# PIC32MM0256GPM028 register map
Vendor: Microchip
Registers are 32-bit, read-write, reset 0x0 unless marked. A register's access mark holds for its fields unless they carry their own. Addresses are absolute, and some are shared; only a register's first bit layout is shown; [hi:lo] are bit positions; {n}, {i} and the like mark numbered series.

## UART1
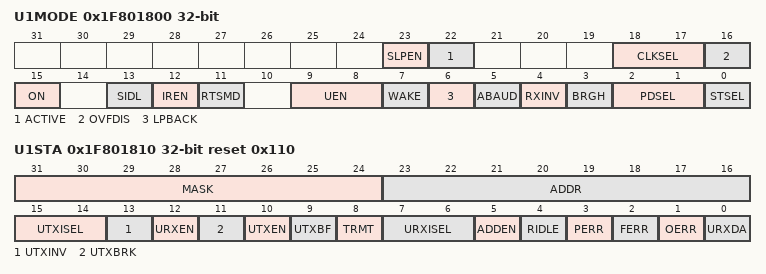
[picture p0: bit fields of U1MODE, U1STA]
0x1F801800 U1MODE
  [23] SLPEN, [22] ACTIVE, [18:17] CLKSEL, [16] OVFDIS, [15] ON, [13] SIDL, [12] IREN, [11] RTSMD, [9:8] UEN, [7] WAKE, [6] LPBACK, [5] ABAUD, [4] RXINV, [3] BRGH, [2:1] PDSEL, [0] STSEL
0x1F801810 U1STA reset 0x110
  [31:24] MASK
  [23:16] ADDR
  [15:14] UTXISEL
  [13] UTXINV
  [12] URXEN
  [11] UTXBRK
  [10] UTXEN
  [9] UTXBF ro
  [8] TRMT ro
  [7:6] URXISEL
  [5] ADDEN
  [4] RIDLE ro
  [3] PERR ro
  [2] FERR ro
  [1] OERR — (can only be cleared)
  [0] URXDA ro
0x1F801820 U1TXREG
  [8:0] U1TXREG
0x1F801830 U1RXREG ro
  [8:0] U1RXREG
0x1F801840 U1BRG
  [19:0] BRG

## UART2
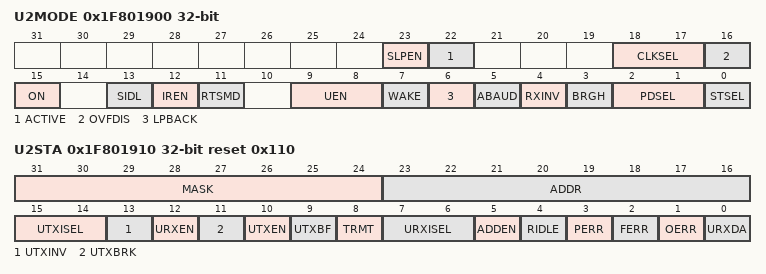
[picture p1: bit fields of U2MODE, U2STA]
0x1F801900 U2MODE
  [23] SLPEN, [22] ACTIVE, [18:17] CLKSEL, [16] OVFDIS, [15] ON, [13] SIDL, [12] IREN, [11] RTSMD, [9:8] UEN, [7] WAKE, [6] LPBACK, [5] ABAUD, [4] RXINV, [3] BRGH, [2:1] PDSEL, [0] STSEL
0x1F801910 U2STA reset 0x110
  [31:24] MASK
  [23:16] ADDR
  [15:14] UTXISEL
  [13] UTXINV
  [12] URXEN
  [11] UTXBRK
  [10] UTXEN
  [9] UTXBF ro
  [8] TRMT ro
  [7:6] URXISEL
  [5] ADDEN
  [4] RIDLE ro
  [3] PERR ro
  [2] FERR ro
  [1] OERR — (can only be cleared)
  [0] URXDA ro
0x1F801920 U2TXREG
  [8:0] U2TXREG
0x1F801930 U2RXREG ro
  [8:0] U2RXREG
0x1F801940 U2BRG
  [19:0] BRG

## UART3
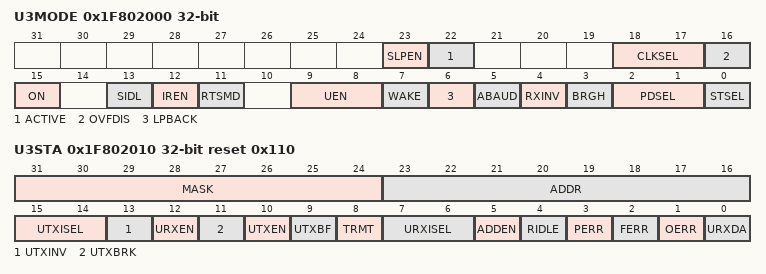
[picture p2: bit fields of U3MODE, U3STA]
0x1F802000 U3MODE
  [23] SLPEN, [22] ACTIVE, [18:17] CLKSEL, [16] OVFDIS, [15] ON, [13] SIDL, [12] IREN, [11] RTSMD, [9:8] UEN, [7] WAKE, [6] LPBACK, [5] ABAUD, [4] RXINV, [3] BRGH, [2:1] PDSEL, [0] STSEL
0x1F802010 U3STA reset 0x110
  [31:24] MASK
  [23:16] ADDR
  [15:14] UTXISEL
  [13] UTXINV
  [12] URXEN
  [11] UTXBRK
  [10] UTXEN
  [9] UTXBF ro
  [8] TRMT ro
  [7:6] URXISEL
  [5] ADDEN
  [4] RIDLE ro
  [3] PERR ro
  [2] FERR ro
  [1] OERR — (can only be cleared)
  [0] URXDA ro
0x1F802020 U3TXREG
  [8:0] U3TXREG
0x1F802030 U3RXREG ro
  [8:0] U3RXREG
0x1F802040 U3BRG
  [19:0] BRG

## ADC
{0x1F802100+0x10*i} ADC1BUF{i} (i=0..21)
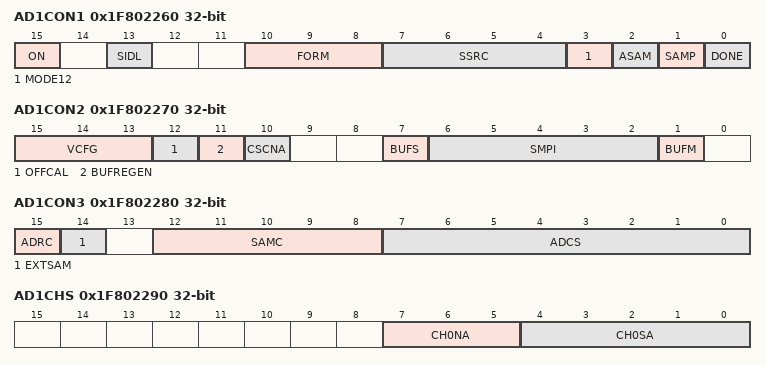
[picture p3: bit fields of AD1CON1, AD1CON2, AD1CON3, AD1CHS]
0x1F802260 AD1CON1
  [15] ON
  [13] SIDL
  [10:8] FORM
  [7:4] SSRC
  [3] MODE12
  [2] ASAM
  [1] SAMP
  [0] DONE — (can only be cleared)
0x1F802270 AD1CON2
  [15:13] VCFG, [12] OFFCAL, [11] BUFREGEN, [10] CSCNA, [7] BUFS ro, [6:2] SMPI, [1] BUFM
0x1F802280 AD1CON3
  [15] ADRC, [14] EXTSAM, [12:8] SAMC, [7:0] ADCS
0x1F802290 AD1CHS
  [7:5] CH0NA, [4:0] CH0SA
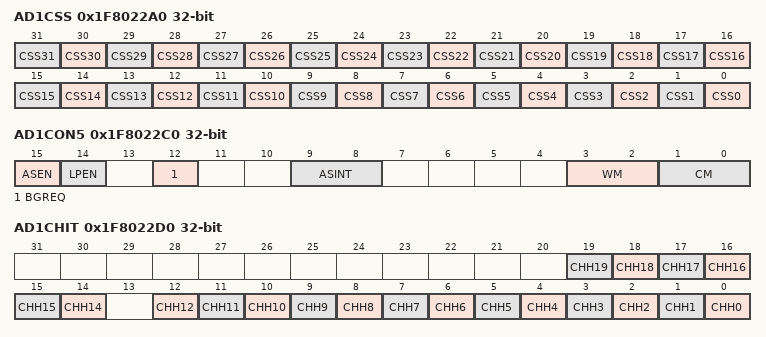
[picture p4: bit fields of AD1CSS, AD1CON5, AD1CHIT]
0x1F8022A0 AD1CSS reset not defined — (power-on value xxxxxxxxxxxxxxxxxxxxxxxxxxxxxxxx)
  [n] CSS{n} (n=0..31)
0x1F8022C0 AD1CON5
  [15] ASEN, [14] LPEN, [12] BGREQ, [9:8] ASINT, [3:2] WM, [1:0] CM
0x1F8022D0 AD1CHIT
  [n] CHH{n} (n=14..19), [n] CHH{n} (n=0..12)

## cmp_control_upb
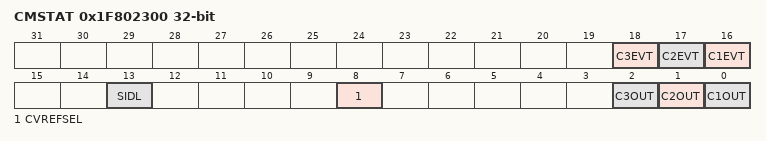
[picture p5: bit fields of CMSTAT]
0x1F802300 CMSTAT
  [18] C3EVT ro, [17] C2EVT ro, [16] C1EVT ro, [13] SIDL, [8] CVREFSEL, [2] C3OUT ro, [1] C2OUT ro, [0] C1OUT ro

## CMP1
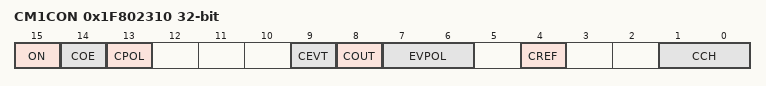
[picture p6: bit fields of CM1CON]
0x1F802310 CM1CON
  [15] ON, [14] COE, [13] CPOL, [9] CEVT, [8] COUT ro, [7:6] EVPOL, [4] CREF, [1:0] CCH

## CMP2
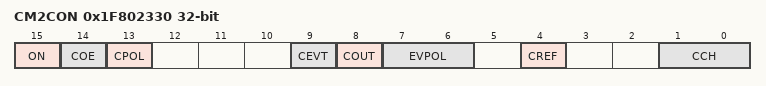
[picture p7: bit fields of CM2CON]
0x1F802330 CM2CON
  [15] ON, [14] COE, [13] CPOL, [9] CEVT, [8] COUT ro, [7:6] EVPOL, [4] CREF, [1:0] CCH

## CMP3
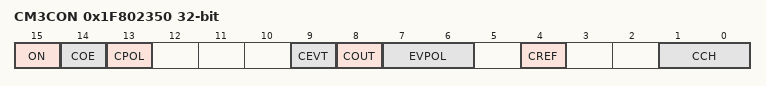
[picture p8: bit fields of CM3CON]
0x1F802350 CM3CON
  [15] ON, [14] COE, [13] CPOL, [9] CEVT, [8] COUT ro, [7:6] EVPOL, [4] CREF, [1:0] CCH

## CDAC1
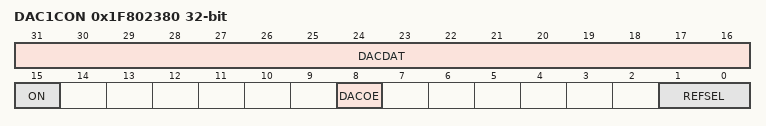
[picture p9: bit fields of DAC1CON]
0x1F802380 DAC1CON — CDAC Control Register
  [31:16] DACDAT — Data Input Register Bits for the CDAC
  [15] ON — CDAC Enable
    0=The CDAC is Disabled; 1=The CDAC is Enabled
  [8] DACOE — CDAC Output Enable
    0=Output is Disabled; drive to pin is floating; 1=Output is Enabled; CDAC voltage is connected to the pin
  [1:0] REFSEL — Reference Source Select
    0=No Reference Selected (no current consumed); 1=Positive Reference Voltage = External Vref+ Pin; 2=Positive Reference Voltage = 2 * Internal Bandgap Reference Voltage; 3=Positive Reference Voltage = AVdd
